AUTOSAR XML (schema 00047)
package /DBCImport/CANTP
  can tp config CanTpConfig_LCAN: communication-cluster=LCAN, can-tp-ecu=WPC
    can tp channel CanTpChannel0: channel-id=0, channel-mode=HALF-DUPLEX-MODE
    tp-connections:
      addressing-format=STANDARD, can-tp-channel=CanTpChannel0, data-pdu=NPdu_LCAN_L_TP_L_WPC_FD_BDC_FD, flow-control-pdu=NPdu_LCAN_L_TP_BDC_FD_L_WPC_FD, max-block-size=0, padding-activation=true, ta-type=PHYSICAL-CAN-FD, tp-sdu=ISignalIPdu_LCAN_L_TP_L_WPC_FD_BDC_FD
      addressing-format=STANDARD, can-tp-channel=CanTpChannel0, data-pdu=NPdu_LCAN_L_TP_BDC_FD_L_WPC_FD, flow-control-pdu=NPdu_LCAN_L_TP_L_WPC_FD_BDC_FD, max-block-size=0, padding-activation=true, ta-type=PHYSICAL-CAN-FD, tp-sdu=ISignalIPdu_LCAN_L_TP_BDC_FD_L_WPC_FD
    can tp node WPC: connector=Conn_WPC_LCAN
package /DBCImport/NMCONFIG
  nm config NmConfig_LCAN
    can nm cluster CanNmCluster_LCAN: communication-cluster=LCAN, nm-pnc-participation=true, nm-msg-cycle-time=0.1, nm-network-timeout=1.0, nm-repeat-message-time=1.2, nm-wait-bus-sleep-time=1.5
      can nm node CanNmNode_LCAN:
        nm-node-id=30
        rx-nm-pdu=[NmPdu_LCAN_NM_CGW_CCU, NmPdu_LCAN_NM_L_DHRR_FD, NmPdu_LCAN_NM_L_UWB_BLE_MST_FD, NmPdu_LCAN_NM_L_UWB_RR_FD, NmPdu_LCAN_NM_L_UWB_BLE_SLV_FD, NmPdu_LCAN_NM_L_UWB_FR_FD, NmPdu_LCAN_NM_L_DHRL_FD, NmPdu_LCAN_NM_L_UWB_TRNK_FD, NmPdu_LCAN_NM_L_UWB_FRNK_FD, NmPdu_LCAN_NM_L_UWB_FL_FD, NmPdu_LCAN_NM_GW_BDC_FD, NmPdu_LCAN_NM_L_UWB_RL_FD, NmPdu_LCAN_NM_L_SAL_FD, NmPdu_LCAN_NM_L_TPMS_FD, NmPdu_LCAN_NM_L_DHL_FD, NmPdu_LCAN_NM_L_DHR_FD]
        tx-nm-pdu=NmPdu_LCAN_NM_L_WPC_FD
        nm-range-config={lower-can-id=402391040, upper-can-id=402391294}
package /DBCImport/SWCComposition
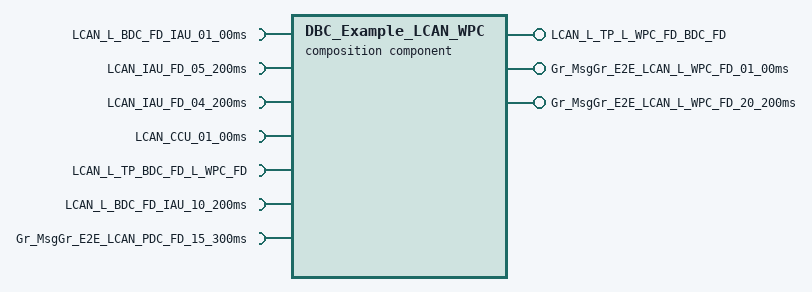
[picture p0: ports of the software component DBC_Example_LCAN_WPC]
  composition sw component type DBC_Example_LCAN_WPC
    provide port LCAN_L_TP_L_WPC_FD_BDC_FD: provided-interface=LCAN_L_TP_L_WPC_FD_BDC_FD
    provide port Gr_MsgGr_E2E_LCAN_L_WPC_FD_01_00ms: provided-interface=Gr_MsgGr_E2E_LCAN_L_WPC_FD_01_00ms
    provide port Gr_MsgGr_E2E_LCAN_L_WPC_FD_20_200ms: provided-interface=Gr_MsgGr_E2E_LCAN_L_WPC_FD_20_200ms
    7 x require port:
      LCAN_L_BDC_FD_IAU_01_00ms: required-interface=LCAN_L_BDC_FD_IAU_01_00ms
      LCAN_IAU_FD_05_200ms: required-interface=LCAN_IAU_FD_05_200ms
      LCAN_IAU_FD_04_200ms: required-interface=LCAN_IAU_FD_04_200ms
      LCAN_CCU_01_00ms: required-interface=LCAN_CCU_01_00ms
      LCAN_L_TP_BDC_FD_L_WPC_FD: required-interface=LCAN_L_TP_BDC_FD_L_WPC_FD
      LCAN_L_BDC_FD_IAU_10_200ms: required-interface=LCAN_L_BDC_FD_IAU_10_200ms
      Gr_MsgGr_E2E_LCAN_PDC_FD_15_300ms: required-interface=Gr_MsgGr_E2E_LCAN_PDC_FD_15_300ms
package /DBCImport/CLUSTERS
  can cluster LCAN: baudrate=500000, protocol-name=CAN, speed=500
    can physical channel LCAN: comm-connectors=Conn_WPC_LCAN
      frame CanFrame_LCAN_L_BDC_FD_IAU_01_00ms: id 0x4000050, frame-length=8, can-addressing-mode=EXTENDED, can-fd-frame-support=true  # [EC] On Event and On Change
        pdu ISignalIPdu_LCAN_L_BDC_FD_IAU_01_00ms: length=8, minimum-delay=0.02, transmission-mode-true-timing=event-controlled-timing={number-of-repetitions=3, repetition-period=0.04}
          signal ISignal_LCAN_L_BDC_FD_IAU_01_00ms_WPC_NFC_Deselect_Cmd: start 24, 2 bit, little-endian, init-value=0, base-type=uint8, compu {phys=raw for raw 0}, transfer-property=TRIGGERED-ON-CHANGE  # NFC Searchig Start/Stop command to WPC
          signal ISignal_LCAN_L_BDC_FD_IAU_01_00ms_WPC2_NFC_Deselect_Cmd: start 26, 2 bit, little-endian, init-value=0, base-type=uint8, compu {phys=raw for raw 0}, transfer-property=TRIGGERED-ON-CHANGE  # NFC Searchig Start/Stop command to WPC#2
      frame CanFrame_LCAN_IAU_FD_05_200ms: id 0x352, frame-length=32, can-addressing-mode=STANDARD, can-fd-frame-support=true  # [PE] Periodic and On Event
        pdu ISignalIPdu_LCAN_IAU_FD_05_200ms: length=32, minimum-delay=0.02, transmission-mode-true-timing={cyclic-timing={time-offset=0.04, time-period=0.2}, event-controlled-timing={number-of-repetitions=3, repetition-period=0.04}}
          signal ISignal_LCAN_IAU_FD_05_200ms_IAU_SharedPhnRegStat: start 116, 2 bit, little-endian, init-value=0, base-type=uint8, compu {phys=raw for raw 0}, transfer-property=TRIGGERED-ON-CHANGE
      frame CanFrame_LCAN_PDC_FD_15_300ms: id 0x2E9, frame-length=32, can-addressing-mode=STANDARD, can-fd-frame-support=true  # [PE] Periodic and On Event
        pdu ISignalIPdu_LCAN_PDC_FD_15_300ms: length=32, minimum-delay=0.02, transmission-mode-true-timing={cyclic-timing={time-offset=0.0, time-period=0.3}, event-controlled-timing={number-of-repetitions=3, repetition-period=0.04}}
          signal ISignal_LCAN_PDC_FD_15_300ms_PDC_FD_Crc15Val: start 0, 16 bit, little-endian, init-value=65535, base-type=uint16, compu {phys=raw for raw 0}, transfer-property=TRIGGERED-ON-CHANGE  # PDC_FD_CyclicRedundancyCheck15Value
          signal ISignal_LCAN_PDC_FD_15_300ms_PDC_FD_AlvCnt15Val: start 16, 8 bit, little-endian, init-value=0, base-type=uint8, compu {phys=raw for raw 0}, transfer-property=TRIGGERED-ON-CHANGE  # PDC_FD_AliveCounter15Value
          signal ISignal_LCAN_PDC_FD_15_300ms_PDC_ResetPreWrngForOthers: start 42, 2 bit, little-endian, init-value=0, base-type=uint8, compu {phys=raw for raw 0}, transfer-property=TRIGGERED-ON-CHANGE  # This is a warning signal for reset. This signal is used for preparing sideeffect of reset by Receivers
          signal ISignal_LCAN_PDC_FD_15_300ms_PDC_ResetReqForOthers: start 46, 2 bit, little-endian, init-value=0, base-type=uint8, compu {phys=raw for raw 0}, transfer-property=TRIGGERED-ON-CHANGE  # This is a request signal for SW reset except for Gateway
          signal ISignal_LCAN_PDC_FD_15_300ms_PDC_FD_15_300ms_E2EReserved: start 248, 8 bit, little-endian, init-value=0, base-type=uint8, compu {phys=0 for raw NaN}
          mapping MsgGr_LCAN_PDC_FD_15_300ms: i-signal-group=MsgGr_E2E_LCAN_PDC_FD_15_300ms, transfer-property=TRIGGERED-ON-CHANGE
      frame CanFrame_LCAN_IAU_FD_04_200ms: id 0x351, frame-length=32, can-addressing-mode=STANDARD, can-fd-frame-support=true  # [PE] Periodic and On Event
        pdu ISignalIPdu_LCAN_IAU_FD_04_200ms: length=32, minimum-delay=0.02, transmission-mode-true-timing={cyclic-timing={time-offset=0.04, time-period=0.2}, event-controlled-timing={number-of-repetitions=3, repetition-period=0.04}}
          signal ISignal_LCAN_IAU_FD_04_200ms_IAU_OwnerPhnRegRVal: start 90, 2 bit, little-endian, init-value=0, base-type=uint8, compu {0=Default, 1=Disable, 2=Enable, 3=Invalid, phys=raw for raw 0}, transfer-property=TRIGGERED-ON-CHANGE  # Vehicle Owner's Phone is Registered for Digital Key function
          signal ISignal_LCAN_IAU_FD_04_200ms_IAU_DKOwnerSwapOption: start 136, 2 bit, little-endian, init-value=0, base-type=uint8, compu {phys=raw for raw 0}, transfer-property=TRIGGERED-ON-CHANGE
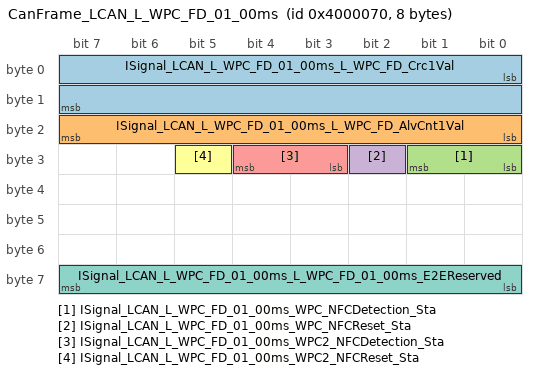
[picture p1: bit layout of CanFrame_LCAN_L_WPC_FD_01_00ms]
      frame CanFrame_LCAN_L_WPC_FD_01_00ms: id 0x4000070, frame-length=8, can-addressing-mode=EXTENDED, can-fd-frame-support=true  # [EC] On Event and On Change
        pdu ISignalIPdu_LCAN_L_WPC_FD_01_00ms: length=8, minimum-delay=0.02, transmission-mode-true-timing=event-controlled-timing={number-of-repetitions=3, repetition-period=0.04}
          signal ISignal_LCAN_L_WPC_FD_01_00ms_L_WPC_FD_Crc1Val: start 0, 16 bit, little-endian, init-value=65535, base-type=uint16, compu {phys=raw for raw 0; unit 0}, unit=0, transfer-property=TRIGGERED-ON-CHANGE  # L_WPC_FD_CyclicRedundancyCheck1Value
          signal ISignal_LCAN_L_WPC_FD_01_00ms_L_WPC_FD_AlvCnt1Val: start 16, 8 bit, little-endian, init-value=0, base-type=uint8, compu {phys=raw for raw 0; unit 0}, unit=0, transfer-property=TRIGGERED-ON-CHANGE  # L_WPC_FD_AliveCounter1Value
          signal ISignal_LCAN_L_WPC_FD_01_00ms_WPC_NFCDetection_Sta: start 24, 2 bit, little-endian, init-value=0, base-type=uint8, compu {phys=raw for raw 0}, transfer-property=TRIGGERED-ON-CHANGE  # Indicate NFC Device is detected or not
          signal ISignal_LCAN_L_WPC_FD_01_00ms_WPC_NFCReset_Sta: start 26, 1 bit, little-endian, init-value=0, base-type=boolean, compu {phys=raw for raw 0}, transfer-property=TRIGGERED-ON-CHANGE  # NFC Deselect Result
          signal ISignal_LCAN_L_WPC_FD_01_00ms_WPC2_NFCDetection_Sta: start 27, 2 bit, little-endian, init-value=0, base-type=uint8, compu {phys=raw for raw 0}, transfer-property=TRIGGERED-ON-CHANGE  # Indicate NFC Device of WPC2 is detected or not in Dual WPC
          signal ISignal_LCAN_L_WPC_FD_01_00ms_WPC2_NFCReset_Sta: start 29, 1 bit, little-endian, init-value=0, base-type=boolean, compu {phys=raw for raw 0}, transfer-property=TRIGGERED-ON-CHANGE  # NFC Deselect Result of WPC2 in DUAL WPC
          signal ISignal_LCAN_L_WPC_FD_01_00ms_L_WPC_FD_01_00ms_E2EReserved: start 56, 8 bit, little-endian, init-value=0, base-type=uint8, compu {phys=0 for raw NaN}
          mapping MsgGr_LCAN_L_WPC_FD_01_00ms: i-signal-group=MsgGr_E2E_LCAN_L_WPC_FD_01_00ms, transfer-property=TRIGGERED-ON-CHANGE
      frame CanFrame_LCAN_CCU_01_00ms: id 0x43F, frame-length=8, can-addressing-mode=STANDARD, can-fd-frame-support=true  # [EC] On Event and On Change
        pdu ISignalIPdu_LCAN_CCU_01_00ms: length=8, minimum-delay=0.02, transmission-mode-true-timing=event-controlled-timing={number-of-repetitions=3, repetition-period=0.04}
          signal ISignal_LCAN_CCU_01_00ms_CCU_ForcedPowerOffReq: start 8, 2 bit, little-endian, init-value=0, base-type=uint8, compu {phys=raw for raw 0}, transfer-property=TRIGGERED-ON-CHANGE  # CCU sends this signal to ICU for the power off logic according to the conditions(vehicle normal mode/there are non-sleep ECUs in 1 hour/all ECUs go into the sleep mode)
      frame CanFrame_LCAN_L_TP_L_WPC_FD_BDC_FD: id 0xC000105, frame-length=32, can-addressing-mode=EXTENDED, can-fd-frame-support=true  # [TP] Transport Protocol
        pdu ISignalIPdu_LCAN_L_TP_L_WPC_FD_BDC_FD: length=512, minimum-delay=0.02, transmission-mode-true-timing=event-controlled-timing={number-of-repetitions=0, repetition-period=0.0}
          signal ISignal_LCAN_L_TP_L_WPC_FD_BDC_FD_LCAN_L_TP_L_WPC_FD_BDC_FD_signal: start 0, 4096 bit, opaque, init-value=512 x 0, compu {phys=raw for raw 0}, implementation-data-type=array512uint8Dynamic, dynamic-length=true, transfer-property=TRIGGERED-WITHOUT-REPETITION
        n pdu NPdu_LCAN_L_TP_L_WPC_FD_BDC_FD: length=32, meta-data-length=0
      frame CanFrame_LCAN_L_TP_BDC_FD_L_WPC_FD: id 0xC000104, frame-length=32, can-addressing-mode=EXTENDED, can-fd-frame-support=true  # [TP] Transport Protocol
        pdu ISignalIPdu_LCAN_L_TP_BDC_FD_L_WPC_FD: length=512, minimum-delay=0.02, transmission-mode-true-timing=event-controlled-timing={number-of-repetitions=0, repetition-period=0.0}
          signal ISignal_LCAN_L_TP_BDC_FD_L_WPC_FD_LCAN_L_TP_BDC_FD_L_WPC_FD_signal: start 0, 4096 bit, opaque, init-value=512 x 0, compu {phys=raw for raw 0}, implementation-data-type=array512uint8Dynamic, dynamic-length=true, transfer-property=TRIGGERED-WITHOUT-REPETITION
        n pdu NPdu_LCAN_L_TP_BDC_FD_L_WPC_FD: length=8, meta-data-length=0
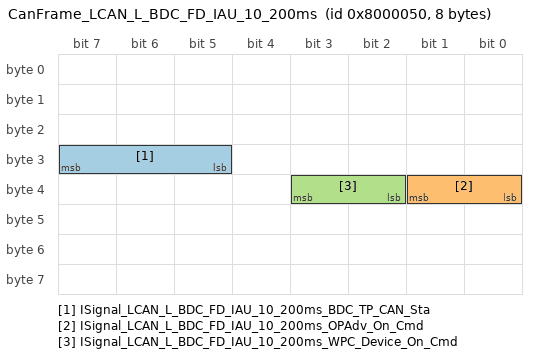
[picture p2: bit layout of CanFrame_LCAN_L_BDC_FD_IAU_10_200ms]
      frame CanFrame_LCAN_L_BDC_FD_IAU_10_200ms: id 0x8000050, frame-length=8, can-addressing-mode=EXTENDED, can-fd-frame-support=true  # [PE] Periodic and On Event
        pdu ISignalIPdu_LCAN_L_BDC_FD_IAU_10_200ms: length=8, minimum-delay=0.02, transmission-mode-true-timing={cyclic-timing={time-offset=0.0, time-period=0.2}, event-controlled-timing={number-of-repetitions=3, repetition-period=0.04}}
          signal ISignal_LCAN_L_BDC_FD_IAU_10_200ms_BDC_TP_CAN_Sta: start 29, 3 bit, little-endian, init-value=0, base-type=uint8, compu {phys=raw for raw 0}, transfer-property=TRIGGERED-ON-CHANGE  # BDC Processing Status
          signal ISignal_LCAN_L_BDC_FD_IAU_10_200ms_OPAdv_On_Cmd: start 32, 2 bit, little-endian, init-value=0, base-type=uint8, compu {phys=raw for raw 0}, transfer-property=TRIGGERED-ON-CHANGE  # BLE Owner Pairing Advertising Reqeust
          signal ISignal_LCAN_L_BDC_FD_IAU_10_200ms_WPC_Device_On_Cmd: start 34, 2 bit, little-endian, init-value=0, base-type=uint8, compu {phys=raw for raw 0}, transfer-property=TRIGGERED-ON-CHANGE  # Inform device on WPC
      frame CanFrame_LCAN_NM_CGW_CCU: id 0x17FC0070, frame-length=32, can-addressing-mode=EXTENDED, can-fd-frame-support=true
        nm pdu NmPdu_LCAN_NM_CGW_CCU: length=32
          signal ISignal_LCAN_NM_CGW_CCU_SNI_CGW_CCU: start 0, 8 bit, little-endian, init-value=0, base-type=uint8, compu {phys=raw for raw 0}, transfer-property=PENDING  # ASR NM Source Node Identifier
          signal ISignal_LCAN_NM_CGW_CCU_CBV_RMR_CGW_CCU: start 8, 1 bit, little-endian, init-value=0, base-type=boolean, compu {phys=raw for raw 0}, transfer-property=PENDING  # ASR NM Control Bit Vector - Repeat Message Request
          signal ISignal_LCAN_NM_CGW_CCU_CBV_NMCoID_CGW_CCU: start 9, 2 bit, little-endian, init-value=0, base-type=uint8, compu {phys=raw for raw 0}, transfer-property=PENDING  # ASR NM Control Bit Vector - ASR NM Coordinator ID
          signal ISignal_LCAN_NM_CGW_CCU_CBV_NMCoSRB_CGW_CCU: start 11, 1 bit, little-endian, init-value=0, base-type=boolean, compu {phys=raw for raw 0}, transfer-property=PENDING  # ASR NM Control Bit Vector - ASR NM Coordinator Sleep Ready Bit
          signal ISignal_LCAN_NM_CGW_CCU_CBV_AWB_CGW_CCU: start 12, 1 bit, little-endian, init-value=0, base-type=boolean, compu {phys=raw for raw 0}, transfer-property=PENDING  # ASR NM Control Bit Vector - Active Wakeup Bit
          signal ISignal_LCAN_NM_CGW_CCU_CBV_PNIB_CGW_CCU: start 14, 1 bit, little-endian, init-value=0, base-type=boolean, compu {phys=raw for raw 0}, transfer-property=PENDING  # ASR NM Control Bit Vector - PN Info Bit
          signal ISignal_LCAN_NM_CGW_CCU_NRR_CGW_CCU: start 16, 8 bit, little-endian, init-value=0, base-type=uint8, compu {phys=raw for raw 0}, transfer-property=PENDING  # ASR NM Network Request Reason
          signal ISignal_LCAN_NM_CGW_CCU_NM_State_CGW_CCU: start 24, 8 bit, little-endian, init-value=0, base-type=uint8, compu {phys=raw for raw 0}, transfer-property=PENDING  # ASR NM State_Current State_Previous State
          signal ISignal_LCAN_NM_CGW_CCU_PNI_CGW_CCU: start 32, 32 bit, little-endian, init-value=0, base-type=uint32, compu {phys=raw for raw 0}, transfer-property=PENDING  # ASR NM Partial Networking Information
          signal ISignal_LCAN_NM_CGW_CCU_PNI_CGW_CCU_1: start 64, 64 bit, opaque, init-value=8 x 0, compu {phys=raw for raw 0}, implementation-data-type=array8uint8, transfer-property=PENDING  # ASR NM Partial Networking Information
          signal ISignal_LCAN_NM_CGW_CCU_PNI_CGW_CCU_2: start 128, 64 bit, opaque, init-value=8 x 0, compu {phys=raw for raw 0}, implementation-data-type=array8uint8, transfer-property=PENDING  # ASR NM Partial Networking Information
          signal ISignal_LCAN_NM_CGW_CCU_PNI_CGW_CCU_3: start 192, 64 bit, opaque, init-value=8 x 0, compu {phys=raw for raw 0}, implementation-data-type=array8uint8, transfer-property=PENDING  # ASR NM Partial Networking Information
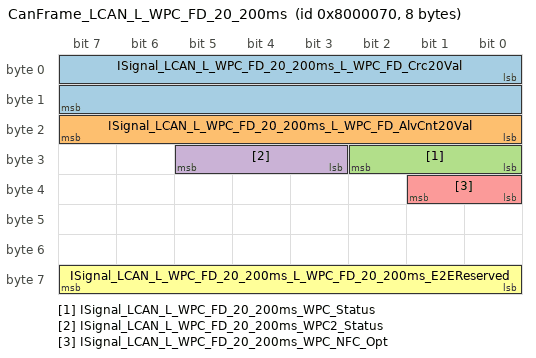
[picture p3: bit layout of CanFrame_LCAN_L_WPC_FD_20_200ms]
      frame CanFrame_LCAN_L_WPC_FD_20_200ms: id 0x8000070, frame-length=8, can-addressing-mode=EXTENDED, can-fd-frame-support=true  # [PE] Periodic and On Event
        pdu ISignalIPdu_LCAN_L_WPC_FD_20_200ms: length=8, minimum-delay=0.02, transmission-mode-true-timing={cyclic-timing={time-offset=0.0, time-period=0.2}, event-controlled-timing={number-of-repetitions=3, repetition-period=0.04}}
          signal ISignal_LCAN_L_WPC_FD_20_200ms_L_WPC_FD_Crc20Val: start 0, 16 bit, little-endian, init-value=65535, base-type=uint16, compu {phys=raw for raw 0; unit 0}, unit=0, transfer-property=TRIGGERED-ON-CHANGE  # L_WPC_FD_CyclicRedundancyCheck20Value
          signal ISignal_LCAN_L_WPC_FD_20_200ms_L_WPC_FD_AlvCnt20Val: start 16, 8 bit, little-endian, init-value=0, base-type=uint8, compu {phys=raw for raw 0; unit 0}, unit=0, transfer-property=TRIGGERED-ON-CHANGE  # L_WPC_FD_AliveCounter20Value
          signal ISignal_LCAN_L_WPC_FD_20_200ms_WPC_Status: start 24, 3 bit, little-endian, init-value=0, base-type=uint8, compu {phys=raw for raw 0}, transfer-property=TRIGGERED-ON-CHANGE  # WPC Processing Status
          signal ISignal_LCAN_L_WPC_FD_20_200ms_WPC2_Status: start 27, 3 bit, little-endian, init-value=0, base-type=uint8, compu {phys=raw for raw 0}, transfer-property=TRIGGERED-ON-CHANGE  # WPC2 Processing Status
          signal ISignal_LCAN_L_WPC_FD_20_200ms_WPC_NFC_Opt: start 32, 2 bit, little-endian, init-value=0, base-type=uint8, compu {phys=raw for raw 0}, transfer-property=TRIGGERED-ON-CHANGE  # WPC NFC Option Applied Signal
          signal ISignal_LCAN_L_WPC_FD_20_200ms_L_WPC_FD_20_200ms_E2EReserved: start 56, 8 bit, little-endian, init-value=0, base-type=uint8, compu {phys=0 for raw NaN}
          mapping MsgGr_LCAN_L_WPC_FD_20_200ms: i-signal-group=MsgGr_E2E_LCAN_L_WPC_FD_20_200ms, transfer-property=TRIGGERED-ON-CHANGE
      frame CanFrame_LCAN_NM_L_DHRR_FD: id 0x17FC002D, frame-length=32, can-addressing-mode=EXTENDED, can-fd-frame-support=true
        nm pdu NmPdu_LCAN_NM_L_DHRR_FD: length=32
          signal ISignal_LCAN_NM_L_DHRR_FD_SNI_L_DHRR_FD: start 0, 8 bit, little-endian, init-value=0, base-type=uint8, compu {phys=raw for raw 0}, transfer-property=PENDING  # ASR NM Source Node Identifier
          signal ISignal_LCAN_NM_L_DHRR_FD_CBV_RMR_L_DHRR_FD: start 8, 1 bit, little-endian, init-value=0, base-type=boolean, compu {phys=raw for raw 0}, transfer-property=PENDING  # ASR NM Control Bit Vector - Repeat Message Request
          signal ISignal_LCAN_NM_L_DHRR_FD_CBV_NMCoID_L_DHRR_FD: start 9, 2 bit, little-endian, init-value=0, base-type=uint8, compu {phys=raw for raw 0}, transfer-property=PENDING  # ASR NM Control Bit Vector - ASR NM Coordinator ID
          signal ISignal_LCAN_NM_L_DHRR_FD_CBV_NMCoSRB_L_DHRR_FD: start 11, 1 bit, little-endian, init-value=0, base-type=boolean, compu {phys=raw for raw 0}, transfer-property=PENDING  # ASR NM Control Bit Vector - ASR NM Coordinator Sleep Ready Bit
          signal ISignal_LCAN_NM_L_DHRR_FD_CBV_AWB_L_DHRR_FD: start 12, 1 bit, little-endian, init-value=0, base-type=boolean, compu {phys=raw for raw 0}, transfer-property=PENDING  # ASR NM Control Bit Vector - Active Wakeup Bit
          signal ISignal_LCAN_NM_L_DHRR_FD_CBV_PNIB_L_DHRR_FD: start 14, 1 bit, little-endian, init-value=0, base-type=boolean, compu {phys=raw for raw 0}, transfer-property=PENDING  # ASR NM Control Bit Vector - PN Info Bit
          signal ISignal_LCAN_NM_L_DHRR_FD_NRR_L_DHRR_FD: start 16, 8 bit, little-endian, init-value=0, base-type=uint8, compu {phys=raw for raw 0}, transfer-property=PENDING  # ASR NM Network Request Reason
          signal ISignal_LCAN_NM_L_DHRR_FD_NM_State_L_DHRR_FD: start 24, 8 bit, little-endian, init-value=0, base-type=uint8, compu {phys=raw for raw 0}, transfer-property=PENDING  # ASR NM State_Current State_Previous State
          signal ISignal_LCAN_NM_L_DHRR_FD_PNI_L_DHRR_FD: start 32, 32 bit, little-endian, init-value=0, base-type=uint32, compu {phys=raw for raw 0}, transfer-property=PENDING  # ASR NM Partial Networking Information
          signal ISignal_LCAN_NM_L_DHRR_FD_PNI_L_DHRR_FD_1: start 64, 64 bit, opaque, init-value=8 x 0, compu {phys=raw for raw 0}, implementation-data-type=array8uint8, transfer-property=PENDING  # ASR NM Partial Networking Information
          signal ISignal_LCAN_NM_L_DHRR_FD_PNI_L_DHRR_FD_2: start 128, 64 bit, opaque, init-value=8 x 0, compu {phys=raw for raw 0}, implementation-data-type=array8uint8, transfer-property=PENDING  # ASR NM Partial Networking Information
          signal ISignal_LCAN_NM_L_DHRR_FD_PNI_L_DHRR_FD_3: start 192, 64 bit, opaque, init-value=8 x 0, compu {phys=raw for raw 0}, implementation-data-type=array8uint8, transfer-property=PENDING  # ASR NM Partial Networking Information
      frame CanFrame_LCAN_NM_L_UWB_BLE_MST_FD: id 0x17FC0020, frame-length=32, can-addressing-mode=EXTENDED, can-fd-frame-support=true
        nm pdu NmPdu_LCAN_NM_L_UWB_BLE_MST_FD: length=32
          signal ISignal_LCAN_NM_L_UWB_BLE_MST_FD_SNI_L_UWB_BLE_MST_FD: start 0, 8 bit, little-endian, init-value=0, base-type=uint8, compu {phys=raw for raw 0}, transfer-property=PENDING  # ASR NM Source Node Identifier
          signal ISignal_LCAN_NM_L_UWB_BLE_MST_FD_CBV_RMR_L_UWB_BLE_MST_FD: start 8, 1 bit, little-endian, init-value=0, base-type=boolean, compu {phys=raw for raw 0}, transfer-property=PENDING  # ASR NM Control Bit Vector - Repeat Message Request
          signal ISignal_LCAN_NM_L_UWB_BLE_MST_FD_CBV_NMCoID_L_UWB_BLE_MST_FD: start 9, 2 bit, little-endian, init-value=0, base-type=uint8, compu {phys=raw for raw 0}, transfer-property=PENDING  # ASR NM Control Bit Vector - ASR NM Coordinator ID
          signal ISignal_LCAN_NM_L_UWB_BLE_MST_FD_CBV_NMCoSRB_L_UWB_BLE_MST_FD: start 11, 1 bit, little-endian, init-value=0, base-type=boolean, compu {phys=raw for raw 0}, transfer-property=PENDING  # ASR NM Control Bit Vector - ASR NM Coordinator Sleep Ready Bit
          signal ISignal_LCAN_NM_L_UWB_BLE_MST_FD_CBV_AWB_L_UWB_BLE_MST_FD: start 12, 1 bit, little-endian, init-value=0, base-type=boolean, compu {phys=raw for raw 0}, transfer-property=PENDING  # ASR NM Control Bit Vector - Active Wakeup Bit
          signal ISignal_LCAN_NM_L_UWB_BLE_MST_FD_CBV_PNIB_L_UWB_BLE_MST_FD: start 14, 1 bit, little-endian, init-value=0, base-type=boolean, compu {phys=raw for raw 0}, transfer-property=PENDING  # ASR NM Control Bit Vector - PN Info Bit
          signal ISignal_LCAN_NM_L_UWB_BLE_MST_FD_NRR_L_UWB_BLE_MST_FD: start 16, 8 bit, little-endian, init-value=0, base-type=uint8, compu {phys=raw for raw 0}, transfer-property=PENDING  # ASR NM Network Request Reason
          signal ISignal_LCAN_NM_L_UWB_BLE_MST_FD_NM_State_L_UWB_BLE_MST_FD: start 24, 8 bit, little-endian, init-value=0, base-type=uint8, compu {phys=raw for raw 0}, transfer-property=PENDING  # ASR NM State_Current State_Previous State
          signal ISignal_LCAN_NM_L_UWB_BLE_MST_FD_PNI_L_UWB_BLE_MST_FD: start 32, 32 bit, little-endian, init-value=0, base-type=uint32, compu {phys=raw for raw 0}, transfer-property=PENDING  # ASR NM Partial Networking Information
          signal ISignal_LCAN_NM_L_UWB_BLE_MST_FD_PNI_L_UWB_BLE_MST_FD_1: start 64, 64 bit, opaque, init-value=8 x 0, compu {phys=raw for raw 0}, implementation-data-type=array8uint8, transfer-property=PENDING  # ASR NM Partial Networking Information
          signal ISignal_LCAN_NM_L_UWB_BLE_MST_FD_PNI_L_UWB_BLE_MST_FD_2: start 128, 64 bit, opaque, init-value=8 x 0, compu {phys=raw for raw 0}, implementation-data-type=array8uint8, transfer-property=PENDING  # ASR NM Partial Networking Information
          signal ISignal_LCAN_NM_L_UWB_BLE_MST_FD_PNI_L_UWB_BLE_MST_FD_3: start 192, 64 bit, opaque, init-value=8 x 0, compu {phys=raw for raw 0}, implementation-data-type=array8uint8, transfer-property=PENDING  # ASR NM Partial Networking Information
      frame CanFrame_LCAN_NM_L_UWB_RR_FD: id 0x17FC0026, frame-length=32, can-addressing-mode=EXTENDED, can-fd-frame-support=true
        nm pdu NmPdu_LCAN_NM_L_UWB_RR_FD: length=32
          signal ISignal_LCAN_NM_L_UWB_RR_FD_SNI_L_UWB_RR_FD: start 0, 8 bit, little-endian, init-value=0, base-type=uint8, compu {phys=raw for raw 0}, transfer-property=PENDING  # ASR NM Source Node Identifier
          signal ISignal_LCAN_NM_L_UWB_RR_FD_CBV_RMR_L_UWB_RR_FD: start 8, 1 bit, little-endian, init-value=0, base-type=boolean, compu {phys=raw for raw 0}, transfer-property=PENDING  # ASR NM Control Bit Vector - Repeat Message Request
          signal ISignal_LCAN_NM_L_UWB_RR_FD_CBV_NMCoID_L_UWB_RR_FD: start 9, 2 bit, little-endian, init-value=0, base-type=uint8, compu {phys=raw for raw 0}, transfer-property=PENDING  # ASR NM Control Bit Vector - ASR NM Coordinator ID
          signal ISignal_LCAN_NM_L_UWB_RR_FD_CBV_NMCoSRB_L_UWB_RR_FD: start 11, 1 bit, little-endian, init-value=0, base-type=boolean, compu {phys=raw for raw 0}, transfer-property=PENDING  # ASR NM Control Bit Vector - ASR NM Coordinator Sleep Ready Bit
          signal ISignal_LCAN_NM_L_UWB_RR_FD_CBV_AWB_L_UWB_RR_FD: start 12, 1 bit, little-endian, init-value=0, base-type=boolean, compu {phys=raw for raw 0}, transfer-property=PENDING  # ASR NM Control Bit Vector - Active Wakeup Bit
          signal ISignal_LCAN_NM_L_UWB_RR_FD_CBV_PNIB_L_UWB_RR_FD: start 14, 1 bit, little-endian, init-value=0, base-type=boolean, compu {phys=raw for raw 0}, transfer-property=PENDING  # ASR NM Control Bit Vector - PN Info Bit
          signal ISignal_LCAN_NM_L_UWB_RR_FD_NRR_L_UWB_RR_FD: start 16, 8 bit, little-endian, init-value=0, base-type=uint8, compu {phys=raw for raw 0}, transfer-property=PENDING  # ASR NM Network Request Reason
          signal ISignal_LCAN_NM_L_UWB_RR_FD_NM_State_L_UWB_RR_FD: start 24, 8 bit, little-endian, init-value=0, base-type=uint8, compu {phys=raw for raw 0}, transfer-property=PENDING  # ASR NM State_Current State_Previous State
          signal ISignal_LCAN_NM_L_UWB_RR_FD_PNI_L_UWB_RR_FD: start 32, 32 bit, little-endian, init-value=0, base-type=uint32, compu {phys=raw for raw 0}, transfer-property=PENDING  # ASR NM Partial Networking Information
          signal ISignal_LCAN_NM_L_UWB_RR_FD_PNI_L_UWB_RR_FD_1: start 64, 64 bit, opaque, init-value=8 x 0, compu {phys=raw for raw 0}, implementation-data-type=array8uint8, transfer-property=PENDING  # ASR NM Partial Networking Information
          signal ISignal_LCAN_NM_L_UWB_RR_FD_PNI_L_UWB_RR_FD_2: start 128, 64 bit, opaque, init-value=8 x 0, compu {phys=raw for raw 0}, implementation-data-type=array8uint8, transfer-property=PENDING  # ASR NM Partial Networking Information
          signal ISignal_LCAN_NM_L_UWB_RR_FD_PNI_L_UWB_RR_FD_3: start 192, 64 bit, opaque, init-value=8 x 0, compu {phys=raw for raw 0}, implementation-data-type=array8uint8, transfer-property=PENDING  # ASR NM Partial Networking Information
      frame CanFrame_LCAN_NM_L_UWB_BLE_SLV_FD: id 0x17FC0021, frame-length=32, can-addressing-mode=EXTENDED, can-fd-frame-support=true
        nm pdu NmPdu_LCAN_NM_L_UWB_BLE_SLV_FD: length=32
          signal ISignal_LCAN_NM_L_UWB_BLE_SLV_FD_SNI_L_UWB_BLE_SLV_FD: start 0, 8 bit, little-endian, init-value=0, base-type=uint8, compu {phys=raw for raw 0}, transfer-property=PENDING  # ASR NM Source Node Identifier
          signal ISignal_LCAN_NM_L_UWB_BLE_SLV_FD_CBV_RMR_L_UWB_BLE_SLV_FD: start 8, 1 bit, little-endian, init-value=0, base-type=boolean, compu {phys=raw for raw 0}, transfer-property=PENDING  # ASR NM Control Bit Vector - Repeat Message Request
          signal ISignal_LCAN_NM_L_UWB_BLE_SLV_FD_CBV_NMCoID_L_UWB_BLE_SLV_FD: start 9, 2 bit, little-endian, init-value=0, base-type=uint8, compu {phys=raw for raw 0}, transfer-property=PENDING  # ASR NM Control Bit Vector - ASR NM Coordinator ID
          signal ISignal_LCAN_NM_L_UWB_BLE_SLV_FD_CBV_NMCoSRB_L_UWB_BLE_SLV_FD: start 11, 1 bit, little-endian, init-value=0, base-type=boolean, compu {phys=raw for raw 0}, transfer-property=PENDING  # ASR NM Control Bit Vector - ASR NM Coordinator Sleep Ready Bit
          signal ISignal_LCAN_NM_L_UWB_BLE_SLV_FD_CBV_AWB_L_UWB_BLE_SLV_FD: start 12, 1 bit, little-endian, init-value=0, base-type=boolean, compu {phys=raw for raw 0}, transfer-property=PENDING  # ASR NM Control Bit Vector - Active Wakeup Bit
          signal ISignal_LCAN_NM_L_UWB_BLE_SLV_FD_CBV_PNIB_L_UWB_BLE_SLV_FD: start 14, 1 bit, little-endian, init-value=0, base-type=boolean, compu {phys=raw for raw 0}, transfer-property=PENDING  # ASR NM Control Bit Vector - PN Info Bit
          signal ISignal_LCAN_NM_L_UWB_BLE_SLV_FD_NRR_L_UWB_BLE_SLV_FD: start 16, 8 bit, little-endian, init-value=0, base-type=uint8, compu {phys=raw for raw 0}, transfer-property=PENDING  # ASR NM Network Request Reason
          signal ISignal_LCAN_NM_L_UWB_BLE_SLV_FD_NM_State_L_UWB_BLE_SLV_FD: start 24, 8 bit, little-endian, init-value=0, base-type=uint8, compu {phys=raw for raw 0}, transfer-property=PENDING  # ASR NM State_Current State_Previous State
          signal ISignal_LCAN_NM_L_UWB_BLE_SLV_FD_PNI_L_UWB_BLE_SLV_FD: start 32, 32 bit, little-endian, init-value=0, base-type=uint32, compu {phys=raw for raw 0}, transfer-property=PENDING  # ASR NM Partial Networking Information
          signal ISignal_LCAN_NM_L_UWB_BLE_SLV_FD_PNI_L_UWB_BLE_SLV_FD_1: start 64, 64 bit, opaque, init-value=8 x 0, compu {phys=raw for raw 0}, implementation-data-type=array8uint8, transfer-property=PENDING  # ASR NM Partial Networking Information
          signal ISignal_LCAN_NM_L_UWB_BLE_SLV_FD_PNI_L_UWB_BLE_SLV_FD_2: start 128, 64 bit, opaque, init-value=8 x 0, compu {phys=raw for raw 0}, implementation-data-type=array8uint8, transfer-property=PENDING  # ASR NM Partial Networking Information
          signal ISignal_LCAN_NM_L_UWB_BLE_SLV_FD_PNI_L_UWB_BLE_SLV_FD_3: start 192, 64 bit, opaque, init-value=8 x 0, compu {phys=raw for raw 0}, implementation-data-type=array8uint8, transfer-property=PENDING  # ASR NM Partial Networking Information
      frame CanFrame_LCAN_NM_L_UWB_FR_FD: id 0x17FC0023, frame-length=32, can-addressing-mode=EXTENDED, can-fd-frame-support=true
        nm pdu NmPdu_LCAN_NM_L_UWB_FR_FD: length=32
          signal ISignal_LCAN_NM_L_UWB_FR_FD_SNI_L_UWB_FR_FD: start 0, 8 bit, little-endian, init-value=0, base-type=uint8, compu {phys=raw for raw 0}, transfer-property=PENDING  # ASR NM Source Node Identifier
          signal ISignal_LCAN_NM_L_UWB_FR_FD_CBV_RMR_L_UWB_FR_FD: start 8, 1 bit, little-endian, init-value=0, base-type=boolean, compu {phys=raw for raw 0}, transfer-property=PENDING  # ASR NM Control Bit Vector - Repeat Message Request
          signal ISignal_LCAN_NM_L_UWB_FR_FD_CBV_NMCoID_L_UWB_FR_FD: start 9, 2 bit, little-endian, init-value=0, base-type=uint8, compu {phys=raw for raw 0}, transfer-property=PENDING  # ASR NM Control Bit Vector - ASR NM Coordinator ID
          signal ISignal_LCAN_NM_L_UWB_FR_FD_CBV_NMCoSRB_L_UWB_FR_FD: start 11, 1 bit, little-endian, init-value=0, base-type=boolean, compu {phys=raw for raw 0}, transfer-property=PENDING  # ASR NM Control Bit Vector - ASR NM Coordinator Sleep Ready Bit
          signal ISignal_LCAN_NM_L_UWB_FR_FD_CBV_AWB_L_UWB_FR_FD: start 12, 1 bit, little-endian, init-value=0, base-type=boolean, compu {phys=raw for raw 0}, transfer-property=PENDING  # ASR NM Control Bit Vector - Active Wakeup Bit
          signal ISignal_LCAN_NM_L_UWB_FR_FD_CBV_PNIB_L_UWB_FR_FD: start 14, 1 bit, little-endian, init-value=0, base-type=boolean, compu {phys=raw for raw 0}, transfer-property=PENDING  # ASR NM Control Bit Vector - PN Info Bit
          signal ISignal_LCAN_NM_L_UWB_FR_FD_NRR_L_UWB_FR_FD: start 16, 8 bit, little-endian, init-value=0, base-type=uint8, compu {phys=raw for raw 0}, transfer-property=PENDING  # ASR NM Network Request Reason
          signal ISignal_LCAN_NM_L_UWB_FR_FD_NM_State_L_UWB_FR_FD: start 24, 8 bit, little-endian, init-value=0, base-type=uint8, compu {phys=raw for raw 0}, transfer-property=PENDING  # ASR NM State_Current State_Previous State
          signal ISignal_LCAN_NM_L_UWB_FR_FD_PNI_L_UWB_FR_FD: start 32, 32 bit, little-endian, init-value=0, base-type=uint32, compu {phys=raw for raw 0}, transfer-property=PENDING  # ASR NM Partial Networking Information
          signal ISignal_LCAN_NM_L_UWB_FR_FD_PNI_L_UWB_FR_FD_1: start 64, 64 bit, opaque, init-value=8 x 0, compu {phys=raw for raw 0}, implementation-data-type=array8uint8, transfer-property=PENDING  # ASR NM Partial Networking Information
          signal ISignal_LCAN_NM_L_UWB_FR_FD_PNI_L_UWB_FR_FD_2: start 128, 64 bit, opaque, init-value=8 x 0, compu {phys=raw for raw 0}, implementation-data-type=array8uint8, transfer-property=PENDING  # ASR NM Partial Networking Information
          signal ISignal_LCAN_NM_L_UWB_FR_FD_PNI_L_UWB_FR_FD_3: start 192, 64 bit, opaque, init-value=8 x 0, compu {phys=raw for raw 0}, implementation-data-type=array8uint8, transfer-property=PENDING  # ASR NM Partial Networking Information
      frame CanFrame_LCAN_NM_L_DHRL_FD: id 0x17FC002C, frame-length=32, can-addressing-mode=EXTENDED, can-fd-frame-support=true
        nm pdu NmPdu_LCAN_NM_L_DHRL_FD: length=32
          signal ISignal_LCAN_NM_L_DHRL_FD_SNI_L_DHRL_FD: start 0, 8 bit, little-endian, init-value=0, base-type=uint8, compu {phys=raw for raw 0}, transfer-property=PENDING  # ASR NM Source Node Identifier
          signal ISignal_LCAN_NM_L_DHRL_FD_CBV_RMR_L_DHRL_FD: start 8, 1 bit, little-endian, init-value=0, base-type=boolean, compu {phys=raw for raw 0}, transfer-property=PENDING  # ASR NM Control Bit Vector - Repeat Message Request
          signal ISignal_LCAN_NM_L_DHRL_FD_CBV_NMCoID_L_DHRL_FD: start 9, 2 bit, little-endian, init-value=0, base-type=uint8, compu {phys=raw for raw 0}, transfer-property=PENDING  # ASR NM Control Bit Vector - ASR NM Coordinator ID
          signal ISignal_LCAN_NM_L_DHRL_FD_CBV_NMCoSRB_L_DHRL_FD: start 11, 1 bit, little-endian, init-value=0, base-type=boolean, compu {phys=raw for raw 0}, transfer-property=PENDING  # ASR NM Control Bit Vector - ASR NM Coordinator Sleep Ready Bit
          signal ISignal_LCAN_NM_L_DHRL_FD_CBV_AWB_L_DHRL_FD: start 12, 1 bit, little-endian, init-value=0, base-type=boolean, compu {phys=raw for raw 0}, transfer-property=PENDING  # ASR NM Control Bit Vector - Active Wakeup Bit
          signal ISignal_LCAN_NM_L_DHRL_FD_CBV_PNIB_L_DHRL_FD: start 14, 1 bit, little-endian, init-value=0, base-type=boolean, compu {phys=raw for raw 0}, transfer-property=PENDING  # ASR NM Control Bit Vector - PN Info Bit
          signal ISignal_LCAN_NM_L_DHRL_FD_NRR_L_DHRL_FD: start 16, 8 bit, little-endian, init-value=0, base-type=uint8, compu {phys=raw for raw 0}, transfer-property=PENDING  # ASR NM Network Request Reason
          signal ISignal_LCAN_NM_L_DHRL_FD_NM_State_L_DHRL_FD: start 24, 8 bit, little-endian, init-value=0, base-type=uint8, compu {phys=raw for raw 0}, transfer-property=PENDING  # ASR NM State_Current State_Previous State
          signal ISignal_LCAN_NM_L_DHRL_FD_PNI_L_DHRL_FD: start 32, 32 bit, little-endian, init-value=0, base-type=uint32, compu {phys=raw for raw 0}, transfer-property=PENDING  # ASR NM Partial Networking Information
          signal ISignal_LCAN_NM_L_DHRL_FD_PNI_L_DHRL_FD_1: start 64, 64 bit, opaque, init-value=8 x 0, compu {phys=raw for raw 0}, implementation-data-type=array8uint8, transfer-property=PENDING  # ASR NM Partial Networking Information
          signal ISignal_LCAN_NM_L_DHRL_FD_PNI_L_DHRL_FD_2: start 128, 64 bit, opaque, init-value=8 x 0, compu {phys=raw for raw 0}, implementation-data-type=array8uint8, transfer-property=PENDING  # ASR NM Partial Networking Information
          signal ISignal_LCAN_NM_L_DHRL_FD_PNI_L_DHRL_FD_3: start 192, 64 bit, opaque, init-value=8 x 0, compu {phys=raw for raw 0}, implementation-data-type=array8uint8, transfer-property=PENDING  # ASR NM Partial Networking Information
      frame CanFrame_LCAN_NM_L_UWB_TRNK_FD: id 0x17FC0027, frame-length=32, can-addressing-mode=EXTENDED, can-fd-frame-support=true
        nm pdu NmPdu_LCAN_NM_L_UWB_TRNK_FD: length=32
          signal ISignal_LCAN_NM_L_UWB_TRNK_FD_SNI_L_UWB_TRNK_FD: start 0, 8 bit, little-endian, init-value=0, base-type=uint8, compu {phys=raw for raw 0}, transfer-property=PENDING  # ASR NM Source Node Identifier
          signal ISignal_LCAN_NM_L_UWB_TRNK_FD_CBV_RMR_L_UWB_TRNK_FD: start 8, 1 bit, little-endian, init-value=0, base-type=boolean, compu {phys=raw for raw 0}, transfer-property=PENDING  # ASR NM Control Bit Vector - Repeat Message Request
          signal ISignal_LCAN_NM_L_UWB_TRNK_FD_CBV_NMCoID_L_UWB_TRNK_FD: start 9, 2 bit, little-endian, init-value=0, base-type=uint8, compu {phys=raw for raw 0}, transfer-property=PENDING  # ASR NM Control Bit Vector - ASR NM Coordinator ID
          signal ISignal_LCAN_NM_L_UWB_TRNK_FD_CBV_NMCoSRB_L_UWB_TRNK_FD: start 11, 1 bit, little-endian, init-value=0, base-type=boolean, compu {phys=raw for raw 0}, transfer-property=PENDING  # ASR NM Control Bit Vector - ASR NM Coordinator Sleep Ready Bit
          signal ISignal_LCAN_NM_L_UWB_TRNK_FD_CBV_AWB_L_UWB_TRNK_FD: start 12, 1 bit, little-endian, init-value=0, base-type=boolean, compu {phys=raw for raw 0}, transfer-property=PENDING  # ASR NM Control Bit Vector - Active Wakeup Bit
          signal ISignal_LCAN_NM_L_UWB_TRNK_FD_CBV_PNIB_L_UWB_TRNK_FD: start 14, 1 bit, little-endian, init-value=0, base-type=boolean, compu {phys=raw for raw 0}, transfer-property=PENDING  # ASR NM Control Bit Vector - PN Info Bit
          signal ISignal_LCAN_NM_L_UWB_TRNK_FD_NRR_L_UWB_TRNK_FD: start 16, 8 bit, little-endian, init-value=0, base-type=uint8, compu {phys=raw for raw 0}, transfer-property=PENDING  # ASR NM Network Request Reason
          signal ISignal_LCAN_NM_L_UWB_TRNK_FD_NM_State_L_UWB_TRNK_FD: start 24, 8 bit, little-endian, init-value=0, base-type=uint8, compu {phys=raw for raw 0}, transfer-property=PENDING  # ASR NM State_Current State_Previous State
          signal ISignal_LCAN_NM_L_UWB_TRNK_FD_PNI_L_UWB_TRNK_FD: start 32, 32 bit, little-endian, init-value=0, base-type=uint32, compu {phys=raw for raw 0}, transfer-property=PENDING  # ASR NM Partial Networking Information
          signal ISignal_LCAN_NM_L_UWB_TRNK_FD_PNI_L_UWB_TRNK_FD_1: start 64, 64 bit, opaque, init-value=8 x 0, compu {phys=raw for raw 0}, implementation-data-type=array8uint8, transfer-property=PENDING  # ASR NM Partial Networking Information
          signal ISignal_LCAN_NM_L_UWB_TRNK_FD_PNI_L_UWB_TRNK_FD_2: start 128, 64 bit, opaque, init-value=8 x 0, compu {phys=raw for raw 0}, implementation-data-type=array8uint8, transfer-property=PENDING  # ASR NM Partial Networking Information
          signal ISignal_LCAN_NM_L_UWB_TRNK_FD_PNI_L_UWB_TRNK_FD_3: start 192, 64 bit, opaque, init-value=8 x 0, compu {phys=raw for raw 0}, implementation-data-type=array8uint8, transfer-property=PENDING  # ASR NM Partial Networking Information
      frame CanFrame_LCAN_NM_L_UWB_FRNK_FD: id 0x17FC0024, frame-length=32, can-addressing-mode=EXTENDED, can-fd-frame-support=true
        nm pdu NmPdu_LCAN_NM_L_UWB_FRNK_FD: length=32
          signal ISignal_LCAN_NM_L_UWB_FRNK_FD_SNI_L_UWB_FRNK_FD: start 0, 8 bit, little-endian, init-value=0, base-type=uint8, compu {phys=raw for raw 0}, transfer-property=PENDING  # ASR NM Source Node Identifier
          signal ISignal_LCAN_NM_L_UWB_FRNK_FD_CBV_RMR_L_UWB_FRNK_FD: start 8, 1 bit, little-endian, init-value=0, base-type=boolean, compu {phys=raw for raw 0}, transfer-property=PENDING  # ASR NM Control Bit Vector - Repeat Message Request
          signal ISignal_LCAN_NM_L_UWB_FRNK_FD_CBV_NMCoID_L_UWB_FRNK_FD: start 9, 2 bit, little-endian, init-value=0, base-type=uint8, compu {phys=raw for raw 0}, transfer-property=PENDING  # ASR NM Control Bit Vector - ASR NM Coordinator ID
          signal ISignal_LCAN_NM_L_UWB_FRNK_FD_CBV_NMCoSRB_L_UWB_FRNK_FD: start 11, 1 bit, little-endian, init-value=0, base-type=boolean, compu {phys=raw for raw 0}, transfer-property=PENDING  # ASR NM Control Bit Vector - ASR NM Coordinator Sleep Ready Bit
          signal ISignal_LCAN_NM_L_UWB_FRNK_FD_CBV_AWB_L_UWB_FRNK_FD: start 12, 1 bit, little-endian, init-value=0, base-type=boolean, compu {phys=raw for raw 0}, transfer-property=PENDING  # ASR NM Control Bit Vector - Active Wakeup Bit
          signal ISignal_LCAN_NM_L_UWB_FRNK_FD_CBV_PNIB_L_UWB_FRNK_FD: start 14, 1 bit, little-endian, init-value=0, base-type=boolean, compu {phys=raw for raw 0}, transfer-property=PENDING  # ASR NM Control Bit Vector - PN Info Bit
          signal ISignal_LCAN_NM_L_UWB_FRNK_FD_NRR_L_UWB_FRNK_FD: start 16, 8 bit, little-endian, init-value=0, base-type=uint8, compu {phys=raw for raw 0}, transfer-property=PENDING  # ASR NM Network Request Reason
          signal ISignal_LCAN_NM_L_UWB_FRNK_FD_NM_State_L_UWB_FRNK_FD: start 24, 8 bit, little-endian, init-value=0, base-type=uint8, compu {phys=raw for raw 0}, transfer-property=PENDING  # ASR NM State_Current State_Previous State
          signal ISignal_LCAN_NM_L_UWB_FRNK_FD_PNI_L_UWB_FRNK_FD: start 32, 32 bit, little-endian, init-value=0, base-type=uint32, compu {phys=raw for raw 0}, transfer-property=PENDING  # ASR NM Partial Networking Information
          signal ISignal_LCAN_NM_L_UWB_FRNK_FD_PNI_L_UWB_FRNK_FD_1: start 64, 64 bit, opaque, init-value=8 x 0, compu {phys=raw for raw 0}, implementation-data-type=array8uint8, transfer-property=PENDING  # ASR NM Partial Networking Information
          signal ISignal_LCAN_NM_L_UWB_FRNK_FD_PNI_L_UWB_FRNK_FD_2: start 128, 64 bit, opaque, init-value=8 x 0, compu {phys=raw for raw 0}, implementation-data-type=array8uint8, transfer-property=PENDING  # ASR NM Partial Networking Information
          signal ISignal_LCAN_NM_L_UWB_FRNK_FD_PNI_L_UWB_FRNK_FD_3: start 192, 64 bit, opaque, init-value=8 x 0, compu {phys=raw for raw 0}, implementation-data-type=array8uint8, transfer-property=PENDING  # ASR NM Partial Networking Information
      frame CanFrame_LCAN_NM_L_UWB_FL_FD: id 0x17FC0022, frame-length=32, can-addressing-mode=EXTENDED, can-fd-frame-support=true
        nm pdu NmPdu_LCAN_NM_L_UWB_FL_FD: length=32
          signal ISignal_LCAN_NM_L_UWB_FL_FD_SNI_L_UWB_FL_FD: start 0, 8 bit, little-endian, init-value=0, base-type=uint8, compu {phys=raw for raw 0}, transfer-property=PENDING  # ASR NM Source Node Identifier
          signal ISignal_LCAN_NM_L_UWB_FL_FD_CBV_RMR_L_UWB_FL_FD: start 8, 1 bit, little-endian, init-value=0, base-type=boolean, compu {phys=raw for raw 0}, transfer-property=PENDING  # ASR NM Control Bit Vector - Repeat Message Request
          signal ISignal_LCAN_NM_L_UWB_FL_FD_CBV_NMCoID_L_UWB_FL_FD: start 9, 2 bit, little-endian, init-value=0, base-type=uint8, compu {phys=raw for raw 0}, transfer-property=PENDING  # ASR NM Control Bit Vector - ASR NM Coordinator ID
          signal ISignal_LCAN_NM_L_UWB_FL_FD_CBV_NMCoSRB_L_UWB_FL_FD: start 11, 1 bit, little-endian, init-value=0, base-type=boolean, compu {phys=raw for raw 0}, transfer-property=PENDING  # ASR NM Control Bit Vector - ASR NM Coordinator Sleep Ready Bit
          signal ISignal_LCAN_NM_L_UWB_FL_FD_CBV_AWB_L_UWB_FL_FD: start 12, 1 bit, little-endian, init-value=0, base-type=boolean, compu {phys=raw for raw 0}, transfer-property=PENDING  # ASR NM Control Bit Vector - Active Wakeup Bit
          signal ISignal_LCAN_NM_L_UWB_FL_FD_CBV_PNIB_L_UWB_FL_FD: start 14, 1 bit, little-endian, init-value=0, base-type=boolean, compu {phys=raw for raw 0}, transfer-property=PENDING  # ASR NM Control Bit Vector - PN Info Bit
          signal ISignal_LCAN_NM_L_UWB_FL_FD_NRR_L_UWB_FL_FD: start 16, 8 bit, little-endian, init-value=0, base-type=uint8, compu {phys=raw for raw 0}, transfer-property=PENDING  # ASR NM Network Request Reason
          signal ISignal_LCAN_NM_L_UWB_FL_FD_NM_State_L_UWB_FL_FD: start 24, 8 bit, little-endian, init-value=0, base-type=uint8, compu {phys=raw for raw 0}, transfer-property=PENDING  # ASR NM State_Current State_Previous State
          signal ISignal_LCAN_NM_L_UWB_FL_FD_PNI_L_UWB_FL_FD: start 32, 32 bit, little-endian, init-value=0, base-type=uint32, compu {phys=raw for raw 0}, transfer-property=PENDING  # ASR NM Partial Networking Information
          signal ISignal_LCAN_NM_L_UWB_FL_FD_PNI_L_UWB_FL_FD_1: start 64, 64 bit, opaque, init-value=8 x 0, compu {phys=raw for raw 0}, implementation-data-type=array8uint8, transfer-property=PENDING  # ASR NM Partial Networking Information
          signal ISignal_LCAN_NM_L_UWB_FL_FD_PNI_L_UWB_FL_FD_2: start 128, 64 bit, opaque, init-value=8 x 0, compu {phys=raw for raw 0}, implementation-data-type=array8uint8, transfer-property=PENDING  # ASR NM Partial Networking Information
          signal ISignal_LCAN_NM_L_UWB_FL_FD_PNI_L_UWB_FL_FD_3: start 192, 64 bit, opaque, init-value=8 x 0, compu {phys=raw for raw 0}, implementation-data-type=array8uint8, transfer-property=PENDING  # ASR NM Partial Networking Information
      frame CanFrame_LCAN_NM_GW_BDC_FD: id 0x17FC0080, frame-length=32, can-addressing-mode=EXTENDED, can-fd-frame-support=true
        nm pdu NmPdu_LCAN_NM_GW_BDC_FD: length=32
          signal ISignal_LCAN_NM_GW_BDC_FD_SNI_GW_BDC_FD: start 0, 8 bit, little-endian, init-value=0, base-type=uint8, compu {phys=raw for raw 0}, transfer-property=PENDING  # ASR NM Source Node Identifier
          signal ISignal_LCAN_NM_GW_BDC_FD_CBV_RMR_GW_BDC_FD: start 8, 1 bit, little-endian, init-value=0, base-type=boolean, compu {phys=raw for raw 0}, transfer-property=PENDING  # ASR NM Control Bit Vector - Repeat Message Request
          signal ISignal_LCAN_NM_GW_BDC_FD_CBV_NMCoID_GW_BDC_FD: start 9, 2 bit, little-endian, init-value=0, base-type=uint8, compu {phys=raw for raw 0}, transfer-property=PENDING  # ASR NM Control Bit Vector - ASR NM Coordinator ID
          signal ISignal_LCAN_NM_GW_BDC_FD_CBV_NMCoSRB_GW_BDC_FD: start 11, 1 bit, little-endian, init-value=0, base-type=boolean, compu {phys=raw for raw 0}, transfer-property=PENDING  # ASR NM Control Bit Vector - ASR NM Coordinator Sleep Ready Bit
          signal ISignal_LCAN_NM_GW_BDC_FD_CBV_AWB_GW_BDC_FD: start 12, 1 bit, little-endian, init-value=0, base-type=boolean, compu {phys=raw for raw 0}, transfer-property=PENDING  # ASR NM Control Bit Vector - Active Wakeup Bit
          signal ISignal_LCAN_NM_GW_BDC_FD_CBV_PNIB_GW_BDC_FD: start 14, 1 bit, little-endian, init-value=0, base-type=boolean, compu {phys=raw for raw 0}, transfer-property=PENDING  # ASR NM Control Bit Vector - PN Info Bit
          signal ISignal_LCAN_NM_GW_BDC_FD_NRR_GW_BDC_FD: start 16, 8 bit, little-endian, init-value=0, base-type=uint8, compu {phys=raw for raw 0}, transfer-property=PENDING  # ASR NM Network Request Reason
          signal ISignal_LCAN_NM_GW_BDC_FD_NM_State_GW_BDC_FD: start 24, 8 bit, little-endian, init-value=0, base-type=uint8, compu {phys=raw for raw 0}, transfer-property=PENDING  # ASR NM State_Current State_Previous State
          signal ISignal_LCAN_NM_GW_BDC_FD_PNI_GW_BDC_FD: start 32, 32 bit, little-endian, init-value=0, base-type=uint32, compu {phys=raw for raw 0}, transfer-property=PENDING  # ASR NM Partial Networking Information
          signal ISignal_LCAN_NM_GW_BDC_FD_PNI_GW_BDC_FD_1: start 64, 64 bit, opaque, init-value=8 x 0, compu {phys=raw for raw 0}, implementation-data-type=array8uint8, transfer-property=PENDING  # ASR NM Partial Networking Information
          signal ISignal_LCAN_NM_GW_BDC_FD_PNI_GW_BDC_FD_2: start 128, 64 bit, opaque, init-value=8 x 0, compu {phys=raw for raw 0}, implementation-data-type=array8uint8, transfer-property=PENDING  # ASR NM Partial Networking Information
          signal ISignal_LCAN_NM_GW_BDC_FD_PNI_GW_BDC_FD_3: start 192, 64 bit, opaque, init-value=8 x 0, compu {phys=raw for raw 0}, implementation-data-type=array8uint8, transfer-property=PENDING  # ASR NM Partial Networking Information
      frame CanFrame_LCAN_NM_L_UWB_RL_FD: id 0x17FC0025, frame-length=32, can-addressing-mode=EXTENDED, can-fd-frame-support=true
        nm pdu NmPdu_LCAN_NM_L_UWB_RL_FD: length=32
          signal ISignal_LCAN_NM_L_UWB_RL_FD_SNI_L_UWB_RL_FD: start 0, 8 bit, little-endian, init-value=0, base-type=uint8, compu {phys=raw for raw 0}, transfer-property=PENDING  # ASR NM Source Node Identifier
          signal ISignal_LCAN_NM_L_UWB_RL_FD_CBV_RMR_L_UWB_RL_FD: start 8, 1 bit, little-endian, init-value=0, base-type=boolean, compu {phys=raw for raw 0}, transfer-property=PENDING  # ASR NM Control Bit Vector - Repeat Message Request
          signal ISignal_LCAN_NM_L_UWB_RL_FD_CBV_NMCoID_L_UWB_RL_FD: start 9, 2 bit, little-endian, init-value=0, base-type=uint8, compu {phys=raw for raw 0}, transfer-property=PENDING  # ASR NM Control Bit Vector - ASR NM Coordinator ID
          signal ISignal_LCAN_NM_L_UWB_RL_FD_CBV_NMCoSRB_L_UWB_RL_FD: start 11, 1 bit, little-endian, init-value=0, base-type=boolean, compu {phys=raw for raw 0}, transfer-property=PENDING  # ASR NM Control Bit Vector - ASR NM Coordinator Sleep Ready Bit
          signal ISignal_LCAN_NM_L_UWB_RL_FD_CBV_AWB_L_UWB_RL_FD: start 12, 1 bit, little-endian, init-value=0, base-type=boolean, compu {phys=raw for raw 0}, transfer-property=PENDING  # ASR NM Control Bit Vector - Active Wakeup Bit
          signal ISignal_LCAN_NM_L_UWB_RL_FD_CBV_PNIB_L_UWB_RL_FD: start 14, 1 bit, little-endian, init-value=0, base-type=boolean, compu {phys=raw for raw 0}, transfer-property=PENDING  # ASR NM Control Bit Vector - PN Info Bit
          signal ISignal_LCAN_NM_L_UWB_RL_FD_NRR_L_UWB_RL_FD: start 16, 8 bit, little-endian, init-value=0, base-type=uint8, compu {phys=raw for raw 0}, transfer-property=PENDING  # ASR NM Network Request Reason
          signal ISignal_LCAN_NM_L_UWB_RL_FD_NM_State_L_UWB_RL_FD: start 24, 8 bit, little-endian, init-value=0, base-type=uint8, compu {phys=raw for raw 0}, transfer-property=PENDING  # ASR NM State_Current State_Previous State
          signal ISignal_LCAN_NM_L_UWB_RL_FD_PNI_L_UWB_RL_FD: start 32, 32 bit, little-endian, init-value=0, base-type=uint32, compu {phys=raw for raw 0}, transfer-property=PENDING  # ASR NM Partial Networking Information
          signal ISignal_LCAN_NM_L_UWB_RL_FD_PNI_L_UWB_RL_FD_1: start 64, 64 bit, opaque, init-value=8 x 0, compu {phys=raw for raw 0}, implementation-data-type=array8uint8, transfer-property=PENDING  # ASR NM Partial Networking Information
          signal ISignal_LCAN_NM_L_UWB_RL_FD_PNI_L_UWB_RL_FD_2: start 128, 64 bit, opaque, init-value=8 x 0, compu {phys=raw for raw 0}, implementation-data-type=array8uint8, transfer-property=PENDING  # ASR NM Partial Networking Information
          signal ISignal_LCAN_NM_L_UWB_RL_FD_PNI_L_UWB_RL_FD_3: start 192, 64 bit, opaque, init-value=8 x 0, compu {phys=raw for raw 0}, implementation-data-type=array8uint8, transfer-property=PENDING  # ASR NM Partial Networking Information
      frame CanFrame_LCAN_NM_L_SAL_FD: id 0x17FC00A9, frame-length=32, can-addressing-mode=EXTENDED, can-fd-frame-support=true
        nm pdu NmPdu_LCAN_NM_L_SAL_FD: length=32
          signal ISignal_LCAN_NM_L_SAL_FD_SNI_L_SAL_FD: start 0, 8 bit, little-endian, init-value=0, base-type=uint8, compu {phys=raw for raw 0}, transfer-property=PENDING  # ASR NM Source Node Identifier
          signal ISignal_LCAN_NM_L_SAL_FD_CBV_RMR_L_SAL_FD: start 8, 1 bit, little-endian, init-value=0, base-type=boolean, compu {phys=raw for raw 0}, transfer-property=PENDING  # ASR NM Control Bit Vector - Repeat Message Request
          signal ISignal_LCAN_NM_L_SAL_FD_CBV_NMCoID_L_SAL_FD: start 9, 2 bit, little-endian, init-value=0, base-type=uint8, compu {phys=raw for raw 0}, transfer-property=PENDING  # ASR NM Control Bit Vector - ASR NM Coordinator ID
          signal ISignal_LCAN_NM_L_SAL_FD_CBV_NMCoSRB_L_SAL_FD: start 11, 1 bit, little-endian, init-value=0, base-type=boolean, compu {phys=raw for raw 0}, transfer-property=PENDING  # ASR NM Control Bit Vector - ASR NM Coordinator Sleep Ready Bit
          signal ISignal_LCAN_NM_L_SAL_FD_CBV_AWB_L_SAL_FD: start 12, 1 bit, little-endian, init-value=0, base-type=boolean, compu {phys=raw for raw 0}, transfer-property=PENDING  # ASR NM Control Bit Vector - Active Wakeup Bit
          signal ISignal_LCAN_NM_L_SAL_FD_CBV_PNIB_L_SAL_FD: start 14, 1 bit, little-endian, init-value=0, base-type=boolean, compu {phys=raw for raw 0}, transfer-property=PENDING  # ASR NM Control Bit Vector - PN Info Bit
          signal ISignal_LCAN_NM_L_SAL_FD_NRR_L_SAL_FD: start 16, 8 bit, little-endian, init-value=0, base-type=uint8, compu {phys=raw for raw 0}, transfer-property=PENDING  # ASR NM Network Request Reason
          signal ISignal_LCAN_NM_L_SAL_FD_NM_State_L_SAL_FD: start 24, 8 bit, little-endian, init-value=0, base-type=uint8, compu {phys=raw for raw 0}, transfer-property=PENDING  # ASR NM State_Current State_Previous State
          signal ISignal_LCAN_NM_L_SAL_FD_PNI_L_SAL_FD: start 32, 32 bit, little-endian, init-value=0, base-type=uint32, compu {phys=raw for raw 0}, transfer-property=PENDING  # ASR NM Partial Networking Information
          signal ISignal_LCAN_NM_L_SAL_FD_PNI_L_SAL_FD_1: start 64, 64 bit, opaque, init-value=8 x 0, compu {phys=raw for raw 0}, implementation-data-type=array8uint8, transfer-property=PENDING  # ASR NM Partial Networking Information
          signal ISignal_LCAN_NM_L_SAL_FD_PNI_L_SAL_FD_2: start 128, 64 bit, opaque, init-value=8 x 0, compu {phys=raw for raw 0}, implementation-data-type=array8uint8, transfer-property=PENDING  # ASR NM Partial Networking Information
          signal ISignal_LCAN_NM_L_SAL_FD_PNI_L_SAL_FD_3: start 192, 64 bit, opaque, init-value=8 x 0, compu {phys=raw for raw 0}, implementation-data-type=array8uint8, transfer-property=PENDING  # ASR NM Partial Networking Information
      frame CanFrame_LCAN_NM_L_WPC_FD: id 0x17FC001E, frame-length=32, can-addressing-mode=EXTENDED, can-fd-frame-support=true
        nm pdu NmPdu_LCAN_NM_L_WPC_FD: length=32
          signal ISignal_LCAN_NM_L_WPC_FD_SNI_L_WPC_FD: start 0, 8 bit, little-endian, init-value=0, base-type=uint8, compu {phys=raw for raw 0}, transfer-property=PENDING  # ASR NM Source Node Identifier
          signal ISignal_LCAN_NM_L_WPC_FD_CBV_RMR_L_WPC_FD: start 8, 1 bit, little-endian, init-value=0, base-type=boolean, compu {phys=raw for raw 0}, transfer-property=PENDING  # ASR NM Control Bit Vector - Repeat Message Request
          signal ISignal_LCAN_NM_L_WPC_FD_CBV_NMCoID_L_WPC_FD: start 9, 2 bit, little-endian, init-value=0, base-type=uint8, compu {phys=raw for raw 0}, transfer-property=PENDING  # ASR NM Control Bit Vector - ASR NM Coordinator ID
          signal ISignal_LCAN_NM_L_WPC_FD_CBV_NMCoSRB_L_WPC_FD: start 11, 1 bit, little-endian, init-value=0, base-type=boolean, compu {phys=raw for raw 0}, transfer-property=PENDING  # ASR NM Control Bit Vector - ASR NM Coordinator Sleep Ready Bit
          signal ISignal_LCAN_NM_L_WPC_FD_CBV_AWB_L_WPC_FD: start 12, 1 bit, little-endian, init-value=0, base-type=boolean, compu {phys=raw for raw 0}, transfer-property=PENDING  # ASR NM Control Bit Vector - Active Wakeup Bit
          signal ISignal_LCAN_NM_L_WPC_FD_CBV_PNIB_L_WPC_FD: start 14, 1 bit, little-endian, init-value=0, base-type=boolean, compu {phys=raw for raw 0}, transfer-property=PENDING  # ASR NM Control Bit Vector - PN Info Bit
          signal ISignal_LCAN_NM_L_WPC_FD_NRR_L_WPC_FD: start 16, 8 bit, little-endian, init-value=0, base-type=uint8, compu {phys=raw for raw 0}, transfer-property=PENDING  # ASR NM Network Request Reason
          signal ISignal_LCAN_NM_L_WPC_FD_NM_State_L_WPC_FD: start 24, 8 bit, little-endian, init-value=0, base-type=uint8, compu {phys=raw for raw 0}, transfer-property=PENDING  # ASR NM State_Current State_Previous State
          signal ISignal_LCAN_NM_L_WPC_FD_PNI_L_WPC_FD: start 32, 32 bit, little-endian, init-value=0, base-type=uint32, compu {phys=raw for raw 0}, transfer-property=PENDING  # ASR NM Partial Networking Information
          signal ISignal_LCAN_NM_L_WPC_FD_PNI_L_WPC_FD_1: start 64, 64 bit, opaque, init-value=8 x 0, compu {phys=raw for raw 0}, implementation-data-type=array8uint8, transfer-property=PENDING  # ASR NM Partial Networking Information
          signal ISignal_LCAN_NM_L_WPC_FD_PNI_L_WPC_FD_2: start 128, 64 bit, opaque, init-value=8 x 0, compu {phys=raw for raw 0}, implementation-data-type=array8uint8, transfer-property=PENDING  # ASR NM Partial Networking Information
          signal ISignal_LCAN_NM_L_WPC_FD_PNI_L_WPC_FD_3: start 192, 64 bit, opaque, init-value=8 x 0, compu {phys=raw for raw 0}, implementation-data-type=array8uint8, transfer-property=PENDING  # ASR NM Partial Networking Information
      frame CanFrame_LCAN_NM_L_TPMS_FD: id 0x17FC0028, frame-length=32, can-addressing-mode=EXTENDED, can-fd-frame-support=true
        nm pdu NmPdu_LCAN_NM_L_TPMS_FD: length=32
          signal ISignal_LCAN_NM_L_TPMS_FD_SNI_L_TPMS_FD: start 0, 8 bit, little-endian, init-value=0, base-type=uint8, compu {phys=raw for raw 0}, transfer-property=PENDING  # ASR NM Source Node Identifier
          signal ISignal_LCAN_NM_L_TPMS_FD_CBV_RMR_L_TPMS_FD: start 8, 1 bit, little-endian, init-value=0, base-type=boolean, compu {phys=raw for raw 0}, transfer-property=PENDING  # ASR NM Control Bit Vector - Repeat Message Request
          signal ISignal_LCAN_NM_L_TPMS_FD_CBV_NMCoID_L_TPMS_FD: start 9, 2 bit, little-endian, init-value=0, base-type=uint8, compu {phys=raw for raw 0}, transfer-property=PENDING  # ASR NM Control Bit Vector - ASR NM Coordinator ID
          signal ISignal_LCAN_NM_L_TPMS_FD_CBV_NMCoSRB_L_TPMS_FD: start 11, 1 bit, little-endian, init-value=0, base-type=boolean, compu {phys=raw for raw 0}, transfer-property=PENDING  # ASR NM Control Bit Vector - ASR NM Coordinator Sleep Ready Bit
          signal ISignal_LCAN_NM_L_TPMS_FD_CBV_AWB_L_TPMS_FD: start 12, 1 bit, little-endian, init-value=0, base-type=boolean, compu {phys=raw for raw 0}, transfer-property=PENDING  # ASR NM Control Bit Vector - Active Wakeup Bit
          signal ISignal_LCAN_NM_L_TPMS_FD_CBV_PNIB_L_TPMS_FD: start 14, 1 bit, little-endian, init-value=0, base-type=boolean, compu {phys=raw for raw 0}, transfer-property=PENDING  # ASR NM Control Bit Vector - PN Info Bit
          signal ISignal_LCAN_NM_L_TPMS_FD_NRR_L_TPMS_FD: start 16, 8 bit, little-endian, init-value=0, base-type=uint8, compu {phys=raw for raw 0}, transfer-property=PENDING  # ASR NM Network Request Reason
          signal ISignal_LCAN_NM_L_TPMS_FD_NM_State_L_TPMS_FD: start 24, 8 bit, little-endian, init-value=0, base-type=uint8, compu {phys=raw for raw 0}, transfer-property=PENDING  # ASR NM State_Current State_Previous State
          signal ISignal_LCAN_NM_L_TPMS_FD_PNI_L_TPMS_FD: start 32, 32 bit, little-endian, init-value=0, base-type=uint32, compu {phys=raw for raw 0}, transfer-property=PENDING  # ASR NM Partial Networking Information
          signal ISignal_LCAN_NM_L_TPMS_FD_PNI_L_TPMS_FD_1: start 64, 64 bit, opaque, init-value=8 x 0, compu {phys=raw for raw 0}, implementation-data-type=array8uint8, transfer-property=PENDING  # ASR NM Partial Networking Information
          signal ISignal_LCAN_NM_L_TPMS_FD_PNI_L_TPMS_FD_2: start 128, 64 bit, opaque, init-value=8 x 0, compu {phys=raw for raw 0}, implementation-data-type=array8uint8, transfer-property=PENDING  # ASR NM Partial Networking Information
          signal ISignal_LCAN_NM_L_TPMS_FD_PNI_L_TPMS_FD_3: start 192, 64 bit, opaque, init-value=8 x 0, compu {phys=raw for raw 0}, implementation-data-type=array8uint8, transfer-property=PENDING  # ASR NM Partial Networking Information
      frame CanFrame_LCAN_NM_L_DHL_FD: id 0x17FC002A, frame-length=32, can-addressing-mode=EXTENDED, can-fd-frame-support=true
        nm pdu NmPdu_LCAN_NM_L_DHL_FD: length=32
          signal ISignal_LCAN_NM_L_DHL_FD_SNI_L_DHL_FD: start 0, 8 bit, little-endian, init-value=0, base-type=uint8, compu {phys=raw for raw 0}, transfer-property=PENDING  # ASR NM Source Node Identifier
          signal ISignal_LCAN_NM_L_DHL_FD_CBV_RMR_L_DHL_FD: start 8, 1 bit, little-endian, init-value=0, base-type=boolean, compu {phys=raw for raw 0}, transfer-property=PENDING  # ASR NM Control Bit Vector - Repeat Message Request
          signal ISignal_LCAN_NM_L_DHL_FD_CBV_NMCoID_L_DHL_FD: start 9, 2 bit, little-endian, init-value=0, base-type=uint8, compu {phys=raw for raw 0}, transfer-property=PENDING  # ASR NM Control Bit Vector - ASR NM Coordinator ID
          signal ISignal_LCAN_NM_L_DHL_FD_CBV_NMCoSRB_L_DHL_FD: start 11, 1 bit, little-endian, init-value=0, base-type=boolean, compu {phys=raw for raw 0}, transfer-property=PENDING  # ASR NM Control Bit Vector - ASR NM Coordinator Sleep Ready Bit
          signal ISignal_LCAN_NM_L_DHL_FD_CBV_AWB_L_DHL_FD: start 12, 1 bit, little-endian, init-value=0, base-type=boolean, compu {phys=raw for raw 0}, transfer-property=PENDING  # ASR NM Control Bit Vector - Active Wakeup Bit
          signal ISignal_LCAN_NM_L_DHL_FD_CBV_PNIB_L_DHL_FD: start 14, 1 bit, little-endian, init-value=0, base-type=boolean, compu {phys=raw for raw 0}, transfer-property=PENDING  # ASR NM Control Bit Vector - PN Info Bit
          signal ISignal_LCAN_NM_L_DHL_FD_NRR_L_DHL_FD: start 16, 8 bit, little-endian, init-value=0, base-type=uint8, compu {phys=raw for raw 0}, transfer-property=PENDING  # ASR NM Network Request Reason
          signal ISignal_LCAN_NM_L_DHL_FD_NM_State_L_DHL_FD: start 24, 8 bit, little-endian, init-value=0, base-type=uint8, compu {phys=raw for raw 0}, transfer-property=PENDING  # ASR NM State_Current State_Previous State
          signal ISignal_LCAN_NM_L_DHL_FD_PNI_L_DHL_FD: start 32, 32 bit, little-endian, init-value=0, base-type=uint32, compu {phys=raw for raw 0}, transfer-property=PENDING  # ASR NM Partial Networking Information
          signal ISignal_LCAN_NM_L_DHL_FD_PNI_L_DHL_FD_1: start 64, 64 bit, opaque, init-value=8 x 0, compu {phys=raw for raw 0}, implementation-data-type=array8uint8, transfer-property=PENDING  # ASR NM Partial Networking Information
          signal ISignal_LCAN_NM_L_DHL_FD_PNI_L_DHL_FD_2: start 128, 64 bit, opaque, init-value=8 x 0, compu {phys=raw for raw 0}, implementation-data-type=array8uint8, transfer-property=PENDING  # ASR NM Partial Networking Information
          signal ISignal_LCAN_NM_L_DHL_FD_PNI_L_DHL_FD_3: start 192, 64 bit, opaque, init-value=8 x 0, compu {phys=raw for raw 0}, implementation-data-type=array8uint8, transfer-property=PENDING  # ASR NM Partial Networking Information
      frame CanFrame_LCAN_NM_L_DHR_FD: id 0x17FC002B, frame-length=32, can-addressing-mode=EXTENDED, can-fd-frame-support=true
        nm pdu NmPdu_LCAN_NM_L_DHR_FD: length=32
          signal ISignal_LCAN_NM_L_DHR_FD_SNI_L_DHR_FD: start 0, 8 bit, little-endian, init-value=0, base-type=uint8, compu {phys=raw for raw 0}, transfer-property=PENDING  # ASR NM Source Node Identifier
          signal ISignal_LCAN_NM_L_DHR_FD_CBV_RMR_L_DHR_FD: start 8, 1 bit, little-endian, init-value=0, base-type=boolean, compu {phys=raw for raw 0}, transfer-property=PENDING  # ASR NM Control Bit Vector - Repeat Message Request
          signal ISignal_LCAN_NM_L_DHR_FD_CBV_NMCoID_L_DHR_FD: start 9, 2 bit, little-endian, init-value=0, base-type=uint8, compu {phys=raw for raw 0}, transfer-property=PENDING  # ASR NM Control Bit Vector - ASR NM Coordinator ID
          signal ISignal_LCAN_NM_L_DHR_FD_CBV_NMCoSRB_L_DHR_FD: start 11, 1 bit, little-endian, init-value=0, base-type=boolean, compu {phys=raw for raw 0}, transfer-property=PENDING  # ASR NM Control Bit Vector - ASR NM Coordinator Sleep Ready Bit
          signal ISignal_LCAN_NM_L_DHR_FD_CBV_AWB_L_DHR_FD: start 12, 1 bit, little-endian, init-value=0, base-type=boolean, compu {phys=raw for raw 0}, transfer-property=PENDING  # ASR NM Control Bit Vector - Active Wakeup Bit
          signal ISignal_LCAN_NM_L_DHR_FD_CBV_PNIB_L_DHR_FD: start 14, 1 bit, little-endian, init-value=0, base-type=boolean, compu {phys=raw for raw 0}, transfer-property=PENDING  # ASR NM Control Bit Vector - PN Info Bit
          signal ISignal_LCAN_NM_L_DHR_FD_NRR_L_DHR_FD: start 16, 8 bit, little-endian, init-value=0, base-type=uint8, compu {phys=raw for raw 0}, transfer-property=PENDING  # ASR NM Network Request Reason
          signal ISignal_LCAN_NM_L_DHR_FD_NM_State_L_DHR_FD: start 24, 8 bit, little-endian, init-value=0, base-type=uint8, compu {phys=raw for raw 0}, transfer-property=PENDING  # ASR NM State_Current State_Previous State
          signal ISignal_LCAN_NM_L_DHR_FD_PNI_L_DHR_FD: start 32, 32 bit, little-endian, init-value=0, base-type=uint32, compu {phys=raw for raw 0}, transfer-property=PENDING  # ASR NM Partial Networking Information
          signal ISignal_LCAN_NM_L_DHR_FD_PNI_L_DHR_FD_1: start 64, 64 bit, opaque, init-value=8 x 0, compu {phys=raw for raw 0}, implementation-data-type=array8uint8, transfer-property=PENDING  # ASR NM Partial Networking Information
          signal ISignal_LCAN_NM_L_DHR_FD_PNI_L_DHR_FD_2: start 128, 64 bit, opaque, init-value=8 x 0, compu {phys=raw for raw 0}, implementation-data-type=array8uint8, transfer-property=PENDING  # ASR NM Partial Networking Information
          signal ISignal_LCAN_NM_L_DHR_FD_PNI_L_DHR_FD_3: start 192, 64 bit, opaque, init-value=8 x 0, compu {phys=raw for raw 0}, implementation-data-type=array8uint8, transfer-property=PENDING  # ASR NM Partial Networking Information
package /DBCImport/IPDUGROUPS
  4 x i signal i pdu group:
    ISignalIPduGroupRx_WPC_LCAN_PNC159: communication-direction=IN, communication-mode=rx
      i-signal-i-pdus:
        ISignalIPdu_LCAN_L_BDC_FD_IAU_01_00ms
        ISignalIPdu_LCAN_IAU_FD_05_200ms
        ISignalIPdu_LCAN_PDC_FD_15_300ms
        ISignalIPdu_LCAN_IAU_FD_04_200ms
        ISignalIPdu_LCAN_CCU_01_00ms
        ISignalIPdu_LCAN_L_TP_BDC_FD_L_WPC_FD
        ISignalIPdu_LCAN_L_BDC_FD_IAU_10_200ms
    ISignalIPduGroupRx_WPC_LCAN_PNC32: communication-direction=IN, communication-mode=rx
      i-signal-i-pdus:
        ISignalIPdu_LCAN_L_BDC_FD_IAU_01_00ms
        ISignalIPdu_LCAN_IAU_FD_05_200ms
        ISignalIPdu_LCAN_PDC_FD_15_300ms
        ISignalIPdu_LCAN_IAU_FD_04_200ms
        ISignalIPdu_LCAN_CCU_01_00ms
        ISignalIPdu_LCAN_L_TP_BDC_FD_L_WPC_FD
        ISignalIPdu_LCAN_L_BDC_FD_IAU_10_200ms
    ISignalIPduGroupTx_WPC_LCAN_PNC159: communication-direction=OUT, communication-mode=tx
      i-signal-i-pdus:
        ISignalIPdu_LCAN_L_WPC_FD_01_00ms
        ISignalIPdu_LCAN_L_TP_L_WPC_FD_BDC_FD
        ISignalIPdu_LCAN_L_WPC_FD_20_200ms
    ISignalIPduGroupTx_WPC_LCAN_PNC32: communication-direction=OUT, communication-mode=tx
      i-signal-i-pdus:
        ISignalIPdu_LCAN_L_WPC_FD_01_00ms
        ISignalIPdu_LCAN_L_TP_L_WPC_FD_BDC_FD
        ISignalIPdu_LCAN_L_WPC_FD_20_200ms
package /DBCImport/INTERFACES
  10 x sender receiver interface:
    Gr_MsgGr_E2E_LCAN_L_WPC_FD_01_00ms
      data MsgGr_E2E_LCAN_L_WPC_FD_01_00ms: type=MsgGr_E2E_LCAN_L_WPC_FD_01_00ms, init-value=fields=[0, 0, 0, 0, 0]
    Gr_MsgGr_E2E_LCAN_L_WPC_FD_20_200ms
      data MsgGr_E2E_LCAN_L_WPC_FD_20_200ms: type=MsgGr_E2E_LCAN_L_WPC_FD_20_200ms, init-value=fields=[0, 0, 0, 0]
    Gr_MsgGr_E2E_LCAN_PDC_FD_15_300ms
      data MsgGr_E2E_LCAN_PDC_FD_15_300ms: type=MsgGr_E2E_LCAN_PDC_FD_15_300ms, init-value=fields=[0, 0, 0]
    LCAN_CCU_01_00ms
      data CCU_ForcedPowerOffReq: base-type=uint8, compu {phys=raw for raw 0}, type=uint8, init-value=0
    LCAN_IAU_FD_04_200ms
      data IAU_DKOwnerSwapOption: base-type=uint8, compu {phys=raw for raw 0}, type=uint8, init-value=0
      data IAU_OwnerPhnRegRVal: base-type=uint8, compu {0=Default, 1=Disable, 2=Enable, 3=Invalid, phys=raw for raw 0}, type=uint8, init-value=0
    LCAN_IAU_FD_05_200ms
      data IAU_SharedPhnRegStat: base-type=uint8, compu {phys=raw for raw 0}, type=uint8, init-value=0
    LCAN_L_BDC_FD_IAU_01_00ms
      data WPC_NFC_Deselect_Cmd: base-type=uint8, compu {phys=raw for raw 0}, type=uint8, init-value=0
      data WPC2_NFC_Deselect_Cmd: base-type=uint8, compu {phys=raw for raw 0}, type=uint8, init-value=0
    LCAN_L_BDC_FD_IAU_10_200ms
      data BDC_TP_CAN_Sta: base-type=uint8, compu {phys=raw for raw 0}, type=uint8, init-value=0
      data OPAdv_On_Cmd: base-type=uint8, compu {phys=raw for raw 0}, type=uint8, init-value=0
      data WPC_Device_On_Cmd: base-type=uint8, compu {phys=raw for raw 0}, type=uint8, init-value=0
    LCAN_L_TP_BDC_FD_L_WPC_FD
      data LCAN_L_TP_BDC_FD_L_WPC_FD_signal: compu {phys=raw for raw 0}, sw-impl-policy=QUEUED, type=array512uint8Dynamic
    LCAN_L_TP_L_WPC_FD_BDC_FD
      data LCAN_L_TP_L_WPC_FD_BDC_FD_signal: compu {phys=raw for raw 0}, sw-impl-policy=QUEUED, type=array512uint8Dynamic
package /DBCImport/ISIGNALGROUPS
  i signal group MsgGr_E2E_LCAN_L_WPC_FD_01_00ms:
    com-based-signal-group-transformations=XfTx_LCAN_P5
    i-signal=[ISignal_LCAN_L_WPC_FD_01_00ms_L_WPC_FD_Crc1Val, ISignal_LCAN_L_WPC_FD_01_00ms_L_WPC_FD_AlvCnt1Val, ISignal_LCAN_L_WPC_FD_01_00ms_WPC_NFCDetection_Sta, ISignal_LCAN_L_WPC_FD_01_00ms_WPC_NFCReset_Sta, ISignal_LCAN_L_WPC_FD_01_00ms_WPC2_NFCDetection_Sta, ISignal_LCAN_L_WPC_FD_01_00ms_WPC2_NFCReset_Sta, ISignal_LCAN_L_WPC_FD_01_00ms_L_WPC_FD_01_00ms_E2EReserved]
    system-signal-group=MsgGr_E2E_LCAN_L_WPC_FD_01_00ms
    end-to-end-transformation-i-signal-props{transformer=XfTechTx_E2EXf_P5, data-ids=67172464, data-length=64}
  i signal group MsgGr_E2E_LCAN_L_WPC_FD_20_200ms:
    com-based-signal-group-transformations=XfTx_LCAN_P5
    i-signal=[ISignal_LCAN_L_WPC_FD_20_200ms_L_WPC_FD_Crc20Val, ISignal_LCAN_L_WPC_FD_20_200ms_L_WPC_FD_AlvCnt20Val, ISignal_LCAN_L_WPC_FD_20_200ms_WPC_Status, ISignal_LCAN_L_WPC_FD_20_200ms_WPC2_Status, ISignal_LCAN_L_WPC_FD_20_200ms_WPC_NFC_Opt, ISignal_LCAN_L_WPC_FD_20_200ms_L_WPC_FD_20_200ms_E2EReserved]
    system-signal-group=MsgGr_E2E_LCAN_L_WPC_FD_20_200ms
    end-to-end-transformation-i-signal-props{transformer=XfTechTx_E2EXf_P5, data-ids=134281328, data-length=64}
  i signal group MsgGr_E2E_LCAN_PDC_FD_15_300ms:
    com-based-signal-group-transformations=XfRx_LCAN_P5
    i-signal=[ISignal_LCAN_PDC_FD_15_300ms_PDC_FD_Crc15Val, ISignal_LCAN_PDC_FD_15_300ms_PDC_FD_AlvCnt15Val, ISignal_LCAN_PDC_FD_15_300ms_PDC_ResetPreWrngForOthers, ISignal_LCAN_PDC_FD_15_300ms_PDC_ResetReqForOthers, ISignal_LCAN_PDC_FD_15_300ms_PDC_FD_15_300ms_E2EReserved]
    system-signal-group=MsgGr_E2E_LCAN_PDC_FD_15_300ms
    end-to-end-transformation-i-signal-props{transformer=XfTechRx_E2EXf_P5, data-ids=64233, data-length=256}
package /DBCImport/UNITS_LCAN
  unit Unit_0: display-name=0
package /DBCImport/ImplementationDataTypes_LCAN
  5 x impl type:
    MsgGr_E2E_LCAN_L_WPC_FD_01_00ms: category=STRUCTURE
      5 x element, all with category=TYPE_REFERENCE:
        WPC_NFCDetection_Sta: implementation-data-type=uint8
        WPC_NFCReset_Sta: implementation-data-type=boolean
        WPC2_NFCDetection_Sta: implementation-data-type=uint8
        WPC2_NFCReset_Sta: implementation-data-type=boolean
        L_WPC_FD_01_00ms_E2EReserved: implementation-data-type=uint8
    MsgGr_E2E_LCAN_L_WPC_FD_20_200ms: category=STRUCTURE
      4 x element, all with category=TYPE_REFERENCE, implementation-data-type=uint8:
        WPC_Status
        WPC2_Status
        WPC_NFC_Opt
        L_WPC_FD_20_200ms_E2EReserved
    MsgGr_E2E_LCAN_PDC_FD_15_300ms: category=STRUCTURE
      element PDC_ResetPreWrngForOthers: implementation-data-type=uint8
      element PDC_ResetReqForOthers: implementation-data-type=uint8
      element PDC_FD_15_300ms_E2EReserved: implementation-data-type=uint8
    array512uint8Dynamic: category=ARRAY
      element uint8: array-size=512, array-size-semantics=VARIABLE-SIZE, implementation-data-type=uint8
    array8uint8: category=ARRAY
      element uint8: array-size=8, array-size-semantics=FIXED-SIZE, implementation-data-type=uint8
